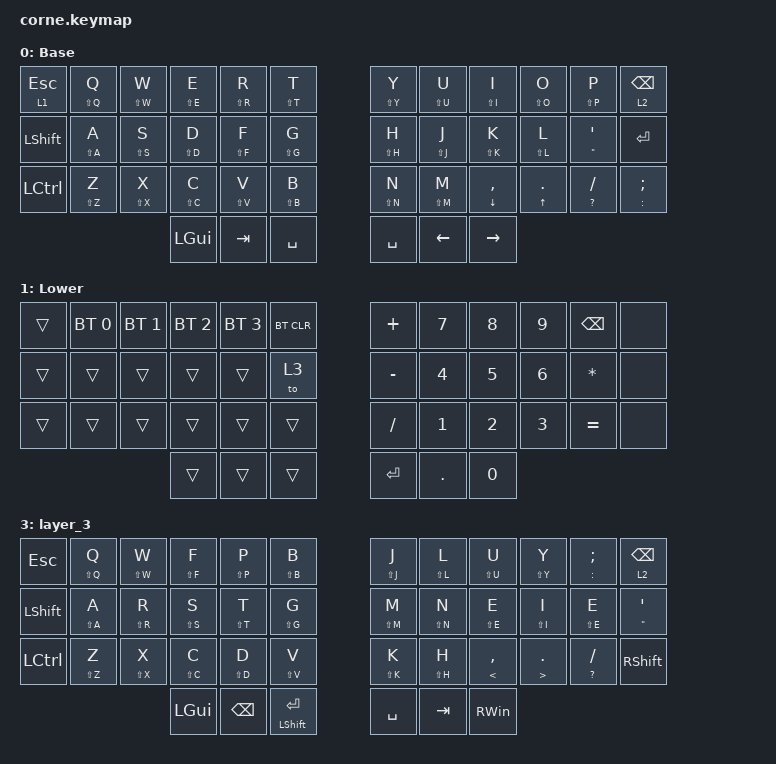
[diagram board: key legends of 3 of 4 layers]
/*
 * Copyright (c) 2020 The ZMK Contributors
 *
 * SPDX-License-Identifier: MIT
 */

#include <behaviors.dtsi>
#include <dt-bindings/zmk/bt.h>
#include <dt-bindings/zmk/keys.h>

&mt {
    flavor = "tap-preferred";
    tapping-term-ms = <250>;
};

/ {
    keymap {
        compatible = "zmk,keymap";

        default_layer {
            // -----------------------------------------------------------------------------------------
            // |  TAB |  Q  |  W  |  E  |  R  |  T  |   |  Y  |  U   |  I  |  O  |  P  | BKSP |
            // | CTRL |  A  |  S  |  D  |  F  |  G  |   |  H  |  J   |  K  |  L  |  ;  |  '   |
            // | SHFT |  Z  |  X  |  C  |  V  |  B  |   |  N  |  M   |  ,  |  .  |  /  | ESC  |
            //                    | GUI | LWR | SPC |   | ENT | RSE  | ALT |

            label = "Base";
            bindings = <
&lt 1 ESC  &mt LS(Q) Q  &mt LS(W) W  &mt LS(E) E  &mt LS(R) R  &mt LS(T) T    &mt LS(Y) Y  &mt LS(U) U     &mt LS(I) I           &mt LS(O) O          &mt LS(P) P                     &lt 2 BACKSPACE
&kp LSHFT  &mt LS(A) A  &mt LS(S) S  &mt LS(D) D  &mt LS(F) F  &mt LS(G) G    &mt LS(H) H  &mt LS(J) J     &mt LS(K) K           &mt LS(L) L          &mt DOUBLE_QUOTES SINGLE_QUOTE  &kp ENTER
&kp LCTRL  &mt LS(Z) Z  &mt LS(X) X  &mt LS(C) C  &mt LS(V) V  &mt LS(B) B    &mt LS(N) N  &mt LS(M) M     &mt DOWN_ARROW COMMA  &mt UP_ARROW PERIOD  &mt QUESTION SLASH              &mt COLON SEMICOLON
                                     &kp LGUI     &kp TAB      &kp SPACE      &kp SPACE    &kp LEFT_ARROW  &kp RIGHT_ARROW
            >;
        };

        lower_layer {
            // -----------------------------------------------------------------------------------------
            // |  TAB |  1  |  2  |  3  |  4  |  5  |   |  6  |  7  |  8  |  9  |  0  | BKSP |
            // | BTCLR| BT1 | BT2 | BT3 | BT4 | BT5 |   | LFT | DWN |  UP | RGT |     |      |
            // | SHFT |     |     |     |     |     |   |     |     |     |     |     |      |
            //                    | GUI |     | SPC |   | ENT |     | ALT |

            label = "Lower";
            bindings = <
&trans  &bt BT_SEL 0  &bt BT_SEL 1  &bt BT_SEL 2  &bt BT_SEL 3  &bt BT_CLR    &kp PLUS   &kp N7   &kp N8  &kp N9  &kp BSPC      &none
&trans  &trans        &trans        &trans        &trans        &to 3         &kp MINUS  &kp N4   &kp N5  &kp N6  &kp ASTERISK  &none
&trans  &trans        &trans        &trans        &trans        &trans        &kp FSLH   &kp N1   &kp N2  &kp N3  &kp EQUAL     &none
                                    &trans        &trans        &trans        &kp ENTER  &kp DOT  &kp N0
            >;
        };

        raise_layer {
            // -----------------------------------------------------------------------------------------
            // |  TAB |  !  |  @  |  #  |  $  |  %  |   |  ^  |  &  |  *  |  (  |  )  | BKSP |
            // | CTRL |     |     |     |     |     |   |  -  |  =  |  [  |  ]  |  \  |  `   |
            // | SHFT |     |     |     |     |     |   |  _  |  +  |  {  |  }  | "|" |  ~   |
            //                    | GUI |     | SPC |   | ENT |     | ALT |

            label = "Raise";
            bindings = <
&trans  &kp EXCL   &kp AT    &kp HASH         &kp DLLR           &kp PRCNT    &trans  &trans  &trans  &trans  &trans  &trans
&trans  &kp CARET  &kp AMPS  &kp KP_MULTIPLY  &kp LPAR           &kp RPAR     &trans  &trans  &trans  &trans  &trans  &trans
&trans  &kp LBRC   &kp RBRC  &kp LBKT         &kp RIGHT_BRACKET  &kp TILDE    &trans  &trans  &trans  &trans  &trans  &mo 3
                             &trans           &trans             &trans       &trans  &trans
            >;
        };

        layer_3 {
            bindings = <
&kp ESCAPE  &mt LS(Q) Q  &mt LS(W) W  &mt LS(F) F  &mt LS(P) P    &mt LS(B) B             &mt LS(J) J  &mt LS(L) L  &mt LS(U) U          &mt LS(Y) Y              &mt COLON SEMICOLON  &lt 2 BACKSPACE
&kp LSHFT   &mt LS(A) A  &mt LS(R) R  &mt LS(S) S  &mt LS(T) T    &mt LS(G) G             &mt LS(M) M  &mt LS(N) N  &mt LS(E) E          &mt LS(I) I              &mt LS(E) E          &mt DOUBLE_QUOTES SINGLE_QUOTE
&kp LCTRL   &mt LS(Z) Z  &mt LS(X) X  &mt LS(C) C  &mt LS(D) D    &mt LS(V) V             &mt LS(K) K  &mt LS(H) H  &mt LESS_THAN COMMA  &mt GREATER_THAN PERIOD  &mt QUESTION SLASH   &kp RIGHT_SHIFT
                                      &kp LGUI     &kp BACKSPACE  &mt LEFT_SHIFT ENTER    &kp SPACE    &kp TAB      &kp RIGHT_WIN
            >;
        };
    };
};
